VERSION ""

NS_ :

BS_:

BU_:

BO_ 16 VALVE_STATUS: 1 Vector__XXX
	SG_ tank_one : 0|1@1+ (0,0) [0|1] "ON/OFF" Vector__XXX
	SG_ tank_two : 1|1@1+ (0,0) [0|1] "ON/OFF" Vector__XXX

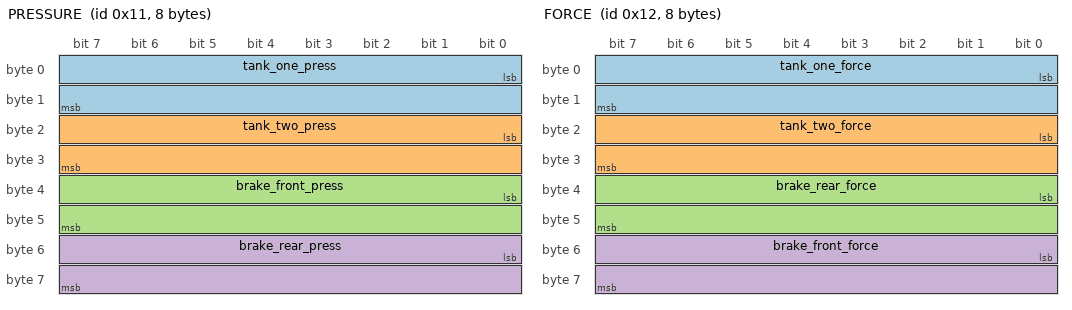
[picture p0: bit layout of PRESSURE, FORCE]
BO_ 17 PRESSURE: 8 Vector__XXX
	SG_ tank_one_press : 0|16@1+ (0.001,0) [0|0] "Bar" Vector__XXX
	SG_ tank_two_press : 16|16@1+ (0.001,0) [0|0] "Bar" Vector__XXX
	SG_ brake_front_press : 32|16@1+ (0.001,0) [0|0] "Bar" Vector__XXX
	SG_ brake_rear_press : 48|16@1+ (0.001,0) [0|0] "Bar" Vector__XXX

BO_ 18 FORCE: 8 Vector__XXX
	SG_ tank_one_force : 0|16@1+ (0.01,0) [0|0] "N" Vector__XXX
	SG_ tank_two_force : 16|16@1+ (0.01,0) [0|0] "N" Vector__XXX
	SG_ brake_rear_force : 32|16@1+ (0.01,0) [0|0] "N" Vector__XXX
	SG_ brake_front_force : 48|16@1+ (0.01,0) [0|0] "N" Vector__XXX
